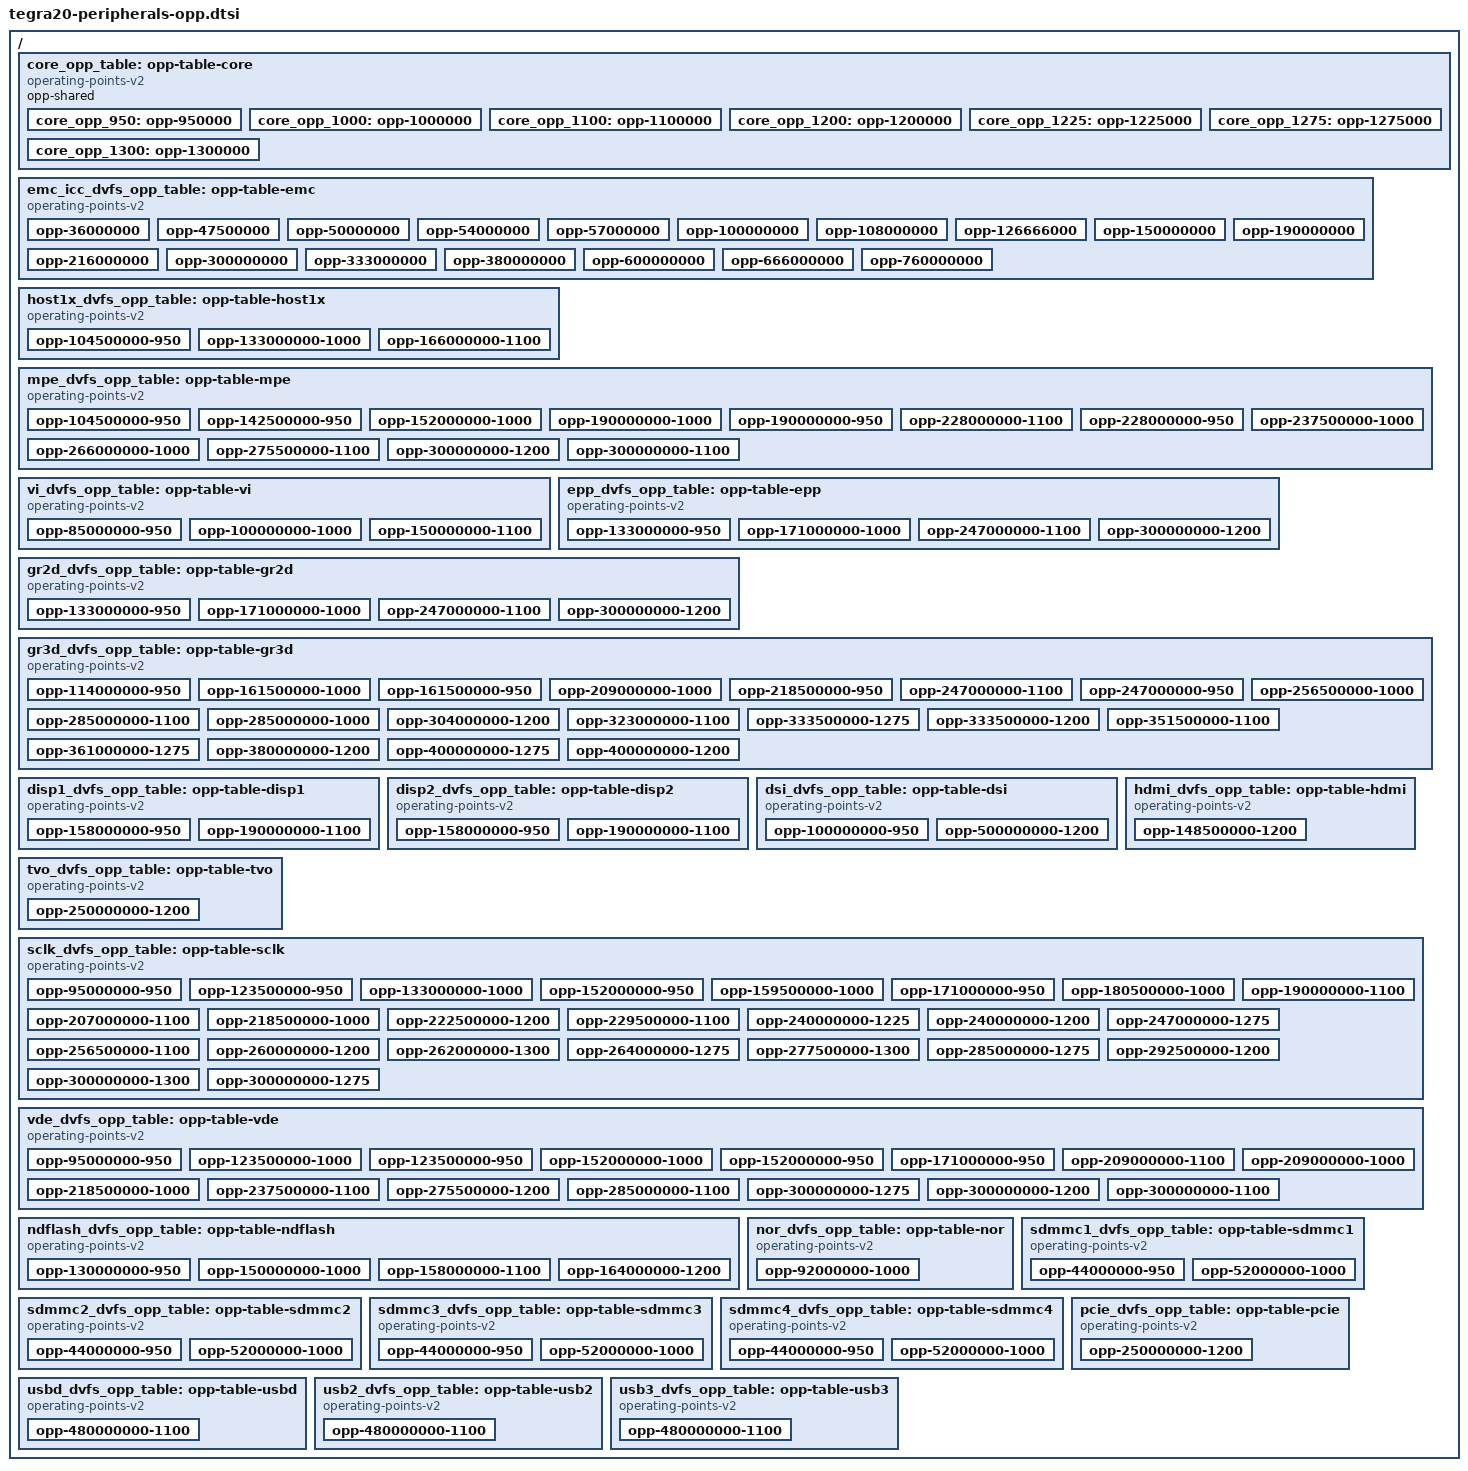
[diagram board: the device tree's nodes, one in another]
// SPDX-License-Identifier: GPL-2.0

/ {
	core_opp_table: opp-table-core {
		compatible = "operating-points-v2";
		opp-shared;

		core_opp_950: opp-950000 {
			opp-microvolt = <950000 950000 1300000>;
			opp-level = <950000>;
		};

		core_opp_1000: opp-1000000 {
			opp-microvolt = <1000000 1000000 1300000>;
			opp-level = <1000000>;
		};

		core_opp_1100: opp-1100000 {
			opp-microvolt = <1100000 1100000 1300000>;
			opp-level = <1100000>;
		};

		core_opp_1200: opp-1200000 {
			opp-microvolt = <1200000 1200000 1300000>;
			opp-level = <1200000>;
		};

		core_opp_1225: opp-1225000 {
			opp-microvolt = <1225000 1225000 1300000>;
			opp-level = <1225000>;
		};

		core_opp_1275: opp-1275000 {
			opp-microvolt = <1275000 1275000 1300000>;
			opp-level = <1275000>;
		};

		core_opp_1300: opp-1300000 {
			opp-microvolt = <1300000 1300000 1300000>;
			opp-level = <1300000>;
		};
	};

	emc_icc_dvfs_opp_table: opp-table-emc {
		compatible = "operating-points-v2";

		opp-36000000 {
			opp-microvolt = <950000 950000 1300000>;
			opp-hz = /bits/ 64 <36000000>;
			opp-supported-hw = <0x000F>;
			required-opps = <&core_opp_950>;
		};

		opp-47500000 {
			opp-microvolt = <950000 950000 1300000>;
			opp-hz = /bits/ 64 <47500000>;
			opp-supported-hw = <0x000F>;
			required-opps = <&core_opp_950>;
		};

		opp-50000000 {
			opp-microvolt = <950000 950000 1300000>;
			opp-hz = /bits/ 64 <50000000>;
			opp-supported-hw = <0x000F>;
			required-opps = <&core_opp_950>;
		};

		opp-54000000 {
			opp-microvolt = <950000 950000 1300000>;
			opp-hz = /bits/ 64 <54000000>;
			opp-supported-hw = <0x000F>;
			required-opps = <&core_opp_950>;
		};

		opp-57000000 {
			opp-microvolt = <950000 950000 1300000>;
			opp-hz = /bits/ 64 <57000000>;
			opp-supported-hw = <0x000F>;
			required-opps = <&core_opp_950>;
		};

		opp-100000000 {
			opp-microvolt = <1000000 1000000 1300000>;
			opp-hz = /bits/ 64 <100000000>;
			opp-supported-hw = <0x000F>;
			required-opps = <&core_opp_1000>;
		};

		opp-108000000 {
			opp-microvolt = <1000000 1000000 1300000>;
			opp-hz = /bits/ 64 <108000000>;
			opp-supported-hw = <0x000F>;
			required-opps = <&core_opp_1000>;
		};

		opp-126666000 {
			opp-microvolt = <1000000 1000000 1300000>;
			opp-hz = /bits/ 64 <126666000>;
			opp-supported-hw = <0x000F>;
			required-opps = <&core_opp_1000>;
		};

		opp-150000000 {
			opp-microvolt = <1000000 1000000 1300000>;
			opp-hz = /bits/ 64 <150000000>;
			opp-supported-hw = <0x000F>;
			required-opps = <&core_opp_1000>;
		};

		opp-190000000 {
			opp-microvolt = <1000000 1000000 1300000>;
			opp-hz = /bits/ 64 <190000000>;
			opp-supported-hw = <0x000F>;
			required-opps = <&core_opp_1000>;
		};

		opp-216000000 {
			opp-microvolt = <1000000 1000000 1300000>;
			opp-hz = /bits/ 64 <216000000>;
			opp-supported-hw = <0x000F>;
			required-opps = <&core_opp_1000>;
			opp-suspend;
		};

		opp-300000000 {
			opp-microvolt = <1000000 1000000 1300000>;
			opp-hz = /bits/ 64 <300000000>;
			opp-supported-hw = <0x000F>;
			required-opps = <&core_opp_1000>;
		};

		opp-333000000 {
			opp-microvolt = <1000000 1000000 1300000>;
			opp-hz = /bits/ 64 <333000000>;
			opp-supported-hw = <0x000F>;
			required-opps = <&core_opp_1000>;
		};

		opp-380000000 {
			opp-microvolt = <1100000 1100000 1300000>;
			opp-hz = /bits/ 64 <380000000>;
			opp-supported-hw = <0x000F>;
			required-opps = <&core_opp_1100>;
		};

		opp-600000000 {
			opp-microvolt = <1200000 1200000 1300000>;
			opp-hz = /bits/ 64 <600000000>;
			opp-supported-hw = <0x000F>;
			required-opps = <&core_opp_1200>;
		};

		opp-666000000 {
			opp-microvolt = <1200000 1200000 1300000>;
			opp-hz = /bits/ 64 <666000000>;
			opp-supported-hw = <0x000F>;
			required-opps = <&core_opp_1200>;
		};

		opp-760000000 {
			opp-microvolt = <1300000 1300000 1300000>;
			opp-hz = /bits/ 64 <760000000>;
			opp-supported-hw = <0x000F>;
			required-opps = <&core_opp_1300>;
		};
	};

	host1x_dvfs_opp_table: opp-table-host1x {
		compatible = "operating-points-v2";

		opp-104500000-950 {
			opp-microvolt = <950000 950000 1300000>;
			opp-hz = /bits/ 64 <104500000>;
			opp-supported-hw = <0x000F>;
			required-opps = <&core_opp_950>;
		};

		opp-133000000-1000 {
			opp-microvolt = <1000000 1000000 1300000>;
			opp-hz = /bits/ 64 <133000000>;
			opp-supported-hw = <0x000F>;
			required-opps = <&core_opp_1000>;
		};

		opp-166000000-1100 {
			opp-microvolt = <1100000 1100000 1300000>;
			opp-hz = /bits/ 64 <166000000>;
			opp-supported-hw = <0x000F>;
			required-opps = <&core_opp_1100>;
		};
	};

	mpe_dvfs_opp_table: opp-table-mpe {
		compatible = "operating-points-v2";

		opp-104500000-950 {
			opp-microvolt = <950000 950000 1300000>;
			opp-hz = /bits/ 64 <104500000>;
			opp-supported-hw = <0x0001>;
			required-opps = <&core_opp_950>;
		};

		opp-142500000-950 {
			opp-microvolt = <950000 950000 1300000>;
			opp-hz = /bits/ 64 <142500000>;
			opp-supported-hw = <0x0002>;
			required-opps = <&core_opp_950>;
		};

		opp-152000000-1000 {
			opp-microvolt = <1000000 1000000 1300000>;
			opp-hz = /bits/ 64 <152000000>;
			opp-supported-hw = <0x0001>;
			required-opps = <&core_opp_1000>;
		};

		opp-190000000-1000 {
			opp-microvolt = <1000000 1000000 1300000>;
			opp-hz = /bits/ 64 <190000000>;
			opp-supported-hw = <0x0002>;
			required-opps = <&core_opp_1000>;
		};

		opp-190000000-950 {
			opp-microvolt = <950000 950000 1300000>;
			opp-hz = /bits/ 64 <190000000>;
			opp-supported-hw = <0x0004>;
			required-opps = <&core_opp_950>;
		};

		opp-228000000-1100 {
			opp-microvolt = <1100000 1100000 1300000>;
			opp-hz = /bits/ 64 <228000000>;
			opp-supported-hw = <0x0001>;
			required-opps = <&core_opp_1100>;
		};

		opp-228000000-950 {
			opp-microvolt = <950000 950000 1300000>;
			opp-hz = /bits/ 64 <228000000>;
			opp-supported-hw = <0x0008>;
			required-opps = <&core_opp_950>;
		};

		opp-237500000-1000 {
			opp-microvolt = <1000000 1000000 1300000>;
			opp-hz = /bits/ 64 <237500000>;
			opp-supported-hw = <0x0004>;
			required-opps = <&core_opp_1000>;
		};

		opp-266000000-1000 {
			opp-microvolt = <1000000 1000000 1300000>;
			opp-hz = /bits/ 64 <266000000>;
			opp-supported-hw = <0x0008>;
			required-opps = <&core_opp_1000>;
		};

		opp-275500000-1100 {
			opp-microvolt = <1100000 1100000 1300000>;
			opp-hz = /bits/ 64 <275500000>;
			opp-supported-hw = <0x0002>;
			required-opps = <&core_opp_1100>;
		};

		opp-300000000-1200 {
			opp-microvolt = <1200000 1200000 1300000>;
			opp-hz = /bits/ 64 <300000000>;
			opp-supported-hw = <0x0003>;
			required-opps = <&core_opp_1200>;
		};

		opp-300000000-1100 {
			opp-microvolt = <1100000 1100000 1300000>;
			opp-hz = /bits/ 64 <300000000>;
			opp-supported-hw = <0x000C>;
			required-opps = <&core_opp_1100>;
		};
	};

	vi_dvfs_opp_table: opp-table-vi {
		compatible = "operating-points-v2";

		opp-85000000-950 {
			opp-microvolt = <950000 950000 1300000>;
			opp-hz = /bits/ 64 <85000000>;
			opp-supported-hw = <0x000F>;
			required-opps = <&core_opp_950>;
		};

		opp-100000000-1000 {
			opp-microvolt = <1000000 1000000 1300000>;
			opp-hz = /bits/ 64 <100000000>;
			opp-supported-hw = <0x000F>;
			required-opps = <&core_opp_1000>;
		};

		opp-150000000-1100 {
			opp-microvolt = <1100000 1100000 1300000>;
			opp-hz = /bits/ 64 <150000000>;
			opp-supported-hw = <0x000F>;
			required-opps = <&core_opp_1100>;
		};
	};

	epp_dvfs_opp_table: opp-table-epp {
		compatible = "operating-points-v2";

		opp-133000000-950 {
			opp-microvolt = <950000 950000 1300000>;
			opp-hz = /bits/ 64 <133000000>;
			opp-supported-hw = <0x000F>;
			required-opps = <&core_opp_950>;
		};

		opp-171000000-1000 {
			opp-microvolt = <1000000 1000000 1300000>;
			opp-hz = /bits/ 64 <171000000>;
			opp-supported-hw = <0x000F>;
			required-opps = <&core_opp_1000>;
		};

		opp-247000000-1100 {
			opp-microvolt = <1100000 1100000 1300000>;
			opp-hz = /bits/ 64 <247000000>;
			opp-supported-hw = <0x000F>;
			required-opps = <&core_opp_1100>;
		};

		opp-300000000-1200 {
			opp-microvolt = <1200000 1200000 1300000>;
			opp-hz = /bits/ 64 <300000000>;
			opp-supported-hw = <0x000F>;
			required-opps = <&core_opp_1200>;
		};
	};

	gr2d_dvfs_opp_table: opp-table-gr2d {
		compatible = "operating-points-v2";

		opp-133000000-950 {
			opp-microvolt = <950000 950000 1300000>;
			opp-hz = /bits/ 64 <133000000>;
			opp-supported-hw = <0x000F>;
			required-opps = <&core_opp_950>;
		};

		opp-171000000-1000 {
			opp-microvolt = <1000000 1000000 1300000>;
			opp-hz = /bits/ 64 <171000000>;
			opp-supported-hw = <0x000F>;
			required-opps = <&core_opp_1000>;
		};

		opp-247000000-1100 {
			opp-microvolt = <1100000 1100000 1300000>;
			opp-hz = /bits/ 64 <247000000>;
			opp-supported-hw = <0x000F>;
			required-opps = <&core_opp_1100>;
		};

		opp-300000000-1200 {
			opp-microvolt = <1200000 1200000 1300000>;
			opp-hz = /bits/ 64 <300000000>;
			opp-supported-hw = <0x000F>;
			required-opps = <&core_opp_1200>;
		};
	};

	gr3d_dvfs_opp_table: opp-table-gr3d {
		compatible = "operating-points-v2";

		opp-114000000-950 {
			opp-microvolt = <950000 950000 1300000>;
			opp-hz = /bits/ 64 <114000000>;
			opp-supported-hw = <0x0001>;
			required-opps = <&core_opp_950>;
		};

		opp-161500000-1000 {
			opp-microvolt = <1000000 1000000 1300000>;
			opp-hz = /bits/ 64 <161500000>;
			opp-supported-hw = <0x0001>;
			required-opps = <&core_opp_1000>;
		};

		opp-161500000-950 {
			opp-microvolt = <950000 950000 1300000>;
			opp-hz = /bits/ 64 <161500000>;
			opp-supported-hw = <0x0002>;
			required-opps = <&core_opp_950>;
		};

		opp-209000000-1000 {
			opp-microvolt = <1000000 1000000 1300000>;
			opp-hz = /bits/ 64 <209000000>;
			opp-supported-hw = <0x0002>;
			required-opps = <&core_opp_1000>;
		};

		opp-218500000-950 {
			opp-microvolt = <950000 950000 1300000>;
			opp-hz = /bits/ 64 <218500000>;
			opp-supported-hw = <0x0004>;
			required-opps = <&core_opp_950>;
		};

		opp-247000000-1100 {
			opp-microvolt = <1100000 1100000 1300000>;
			opp-hz = /bits/ 64 <247000000>;
			opp-supported-hw = <0x0001>;
			required-opps = <&core_opp_1100>;
		};

		opp-247000000-950 {
			opp-microvolt = <950000 950000 1300000>;
			opp-hz = /bits/ 64 <247000000>;
			opp-supported-hw = <0x0008>;
			required-opps = <&core_opp_950>;
		};

		opp-256500000-1000 {
			opp-microvolt = <1000000 1000000 1300000>;
			opp-hz = /bits/ 64 <256500000>;
			opp-supported-hw = <0x0004>;
			required-opps = <&core_opp_1000>;
		};

		opp-285000000-1100 {
			opp-microvolt = <1100000 1100000 1300000>;
			opp-hz = /bits/ 64 <285000000>;
			opp-supported-hw = <0x0002>;
			required-opps = <&core_opp_1100>;
		};

		opp-285000000-1000 {
			opp-microvolt = <1000000 1000000 1300000>;
			opp-hz = /bits/ 64 <285000000>;
			opp-supported-hw = <0x0008>;
			required-opps = <&core_opp_1000>;
		};

		opp-304000000-1200 {
			opp-microvolt = <1200000 1200000 1300000>;
			opp-hz = /bits/ 64 <304000000>;
			opp-supported-hw = <0x0001>;
			required-opps = <&core_opp_1200>;
		};

		opp-323000000-1100 {
			opp-microvolt = <1100000 1100000 1300000>;
			opp-hz = /bits/ 64 <323000000>;
			opp-supported-hw = <0x0004>;
			required-opps = <&core_opp_1100>;
		};

		opp-333500000-1275 {
			opp-microvolt = <1275000 1275000 1300000>;
			opp-hz = /bits/ 64 <333500000>;
			opp-supported-hw = <0x0001>;
			required-opps = <&core_opp_1275>;
		};

		opp-333500000-1200 {
			opp-microvolt = <1200000 1200000 1300000>;
			opp-hz = /bits/ 64 <333500000>;
			opp-supported-hw = <0x0002>;
			required-opps = <&core_opp_1200>;
		};

		opp-351500000-1100 {
			opp-microvolt = <1100000 1100000 1300000>;
			opp-hz = /bits/ 64 <351500000>;
			opp-supported-hw = <0x0008>;
			required-opps = <&core_opp_1100>;
		};

		opp-361000000-1275 {
			opp-microvolt = <1275000 1275000 1300000>;
			opp-hz = /bits/ 64 <361000000>;
			opp-supported-hw = <0x0002>;
			required-opps = <&core_opp_1275>;
		};

		opp-380000000-1200 {
			opp-microvolt = <1200000 1200000 1300000>;
			opp-hz = /bits/ 64 <380000000>;
			opp-supported-hw = <0x0004>;
			required-opps = <&core_opp_1200>;
		};

		opp-400000000-1275 {
			opp-microvolt = <1275000 1275000 1300000>;
			opp-hz = /bits/ 64 <400000000>;
			opp-supported-hw = <0x0004>;
			required-opps = <&core_opp_1275>;
		};

		opp-400000000-1200 {
			opp-microvolt = <1200000 1200000 1300000>;
			opp-hz = /bits/ 64 <400000000>;
			opp-supported-hw = <0x0008>;
			required-opps = <&core_opp_1200>;
		};
	};

	disp1_dvfs_opp_table: opp-table-disp1 {
		compatible = "operating-points-v2";

		opp-158000000-950 {
			opp-microvolt = <950000 950000 1300000>;
			opp-hz = /bits/ 64 <158000000>;
			opp-supported-hw = <0x000F>;
			required-opps = <&core_opp_950>;
		};

		opp-190000000-1100 {
			opp-microvolt = <1100000 1100000 1300000>;
			opp-hz = /bits/ 64 <190000000>;
			opp-supported-hw = <0x000F>;
			required-opps = <&core_opp_1100>;
		};
	};

	disp2_dvfs_opp_table: opp-table-disp2 {
		compatible = "operating-points-v2";

		opp-158000000-950 {
			opp-microvolt = <950000 950000 1300000>;
			opp-hz = /bits/ 64 <158000000>;
			opp-supported-hw = <0x000F>;
			required-opps = <&core_opp_950>;
		};

		opp-190000000-1100 {
			opp-microvolt = <1100000 1100000 1300000>;
			opp-hz = /bits/ 64 <190000000>;
			opp-supported-hw = <0x000F>;
			required-opps = <&core_opp_1100>;
		};
	};

	dsi_dvfs_opp_table: opp-table-dsi {
		compatible = "operating-points-v2";

		opp-100000000-950 {
			opp-microvolt = <950000 950000 1300000>;
			opp-hz = /bits/ 64 <100000000>;
			opp-supported-hw = <0x000F>;
			required-opps = <&core_opp_950>;
		};

		opp-500000000-1200 {
			opp-microvolt = <1200000 1200000 1300000>;
			opp-hz = /bits/ 64 <500000000>;
			opp-supported-hw = <0x000F>;
			required-opps = <&core_opp_1200>;
		};
	};

	hdmi_dvfs_opp_table: opp-table-hdmi {
		compatible = "operating-points-v2";

		opp-148500000-1200 {
			opp-microvolt = <1200000 1200000 1300000>;
			opp-hz = /bits/ 64 <148500000>;
			opp-supported-hw = <0x000F>;
			required-opps = <&core_opp_1200>;
		};
	};

	tvo_dvfs_opp_table: opp-table-tvo {
		compatible = "operating-points-v2";

		opp-250000000-1200 {
			opp-microvolt = <1200000 1200000 1300000>;
			opp-hz = /bits/ 64 <250000000>;
			opp-supported-hw = <0x000F>;
			required-opps = <&core_opp_1200>;
		};
	};

	sclk_dvfs_opp_table: opp-table-sclk {
		compatible = "operating-points-v2";

		opp-95000000-950 {
			opp-microvolt = <950000 950000 1300000>;
			opp-hz = /bits/ 64 <95000000>;
			opp-supported-hw = <0x0001>;
			required-opps = <&core_opp_950>;
		};

		opp-123500000-950 {
			opp-microvolt = <950000 950000 1300000>;
			opp-hz = /bits/ 64 <123500000>;
			opp-supported-hw = <0x0002>;
			required-opps = <&core_opp_950>;
		};

		opp-133000000-1000 {
			opp-microvolt = <1000000 1000000 1300000>;
			opp-hz = /bits/ 64 <133000000>;
			opp-supported-hw = <0x0001>;
			required-opps = <&core_opp_1000>;
		};

		opp-152000000-950 {
			opp-microvolt = <950000 950000 1300000>;
			opp-hz = /bits/ 64 <152000000>;
			opp-supported-hw = <0x0004>;
			required-opps = <&core_opp_950>;
		};

		opp-159500000-1000 {
			opp-microvolt = <1000000 1000000 1300000>;
			opp-hz = /bits/ 64 <159500000>;
			opp-supported-hw = <0x0002>;
			required-opps = <&core_opp_1000>;
		};

		opp-171000000-950 {
			opp-microvolt = <950000 950000 1300000>;
			opp-hz = /bits/ 64 <171000000>;
			opp-supported-hw = <0x0008>;
			required-opps = <&core_opp_950>;
		};

		opp-180500000-1000 {
			opp-microvolt = <1000000 1000000 1300000>;
			opp-hz = /bits/ 64 <180500000>;
			opp-supported-hw = <0x0004>;
			required-opps = <&core_opp_1000>;
		};

		opp-190000000-1100 {
			opp-microvolt = <1100000 1100000 1300000>;
			opp-hz = /bits/ 64 <190000000>;
			opp-supported-hw = <0x0001>;
			required-opps = <&core_opp_1100>;
		};

		opp-207000000-1100 {
			opp-microvolt = <1100000 1100000 1300000>;
			opp-hz = /bits/ 64 <207000000>;
			opp-supported-hw = <0x0002>;
			required-opps = <&core_opp_1100>;
		};

		opp-218500000-1000 {
			opp-microvolt = <1000000 1000000 1300000>;
			opp-hz = /bits/ 64 <218500000>;
			opp-supported-hw = <0x0008>;
			required-opps = <&core_opp_1000>;
		};

		opp-222500000-1200 {
			opp-microvolt = <1200000 1200000 1300000>;
			opp-hz = /bits/ 64 <222500000>;
			opp-supported-hw = <0x0001>;
			required-opps = <&core_opp_1200>;
		};

		opp-229500000-1100 {
			opp-microvolt = <1100000 1100000 1300000>;
			opp-hz = /bits/ 64 <229500000>;
			opp-supported-hw = <0x0004>;
			required-opps = <&core_opp_1100>;
		};

		opp-240000000-1225 {
			opp-microvolt = <1225000 1225000 1300000>;
			opp-hz = /bits/ 64 <240000000>;
			opp-supported-hw = <0x0001>;
			required-opps = <&core_opp_1225>;
		};

		opp-240000000-1200 {
			opp-microvolt = <1200000 1200000 1300000>;
			opp-hz = /bits/ 64 <240000000>;
			opp-supported-hw = <0x0002>;
			required-opps = <&core_opp_1200>;
		};

		opp-247000000-1275 {
			opp-microvolt = <1275000 1275000 1300000>;
			opp-hz = /bits/ 64 <247000000>;
			opp-supported-hw = <0x0001>;
			required-opps = <&core_opp_1275>;
		};

		opp-256500000-1100 {
			opp-microvolt = <1100000 1100000 1300000>;
			opp-hz = /bits/ 64 <256500000>;
			opp-supported-hw = <0x0008>;
			required-opps = <&core_opp_1100>;
		};

		opp-260000000-1200 {
			opp-microvolt = <1200000 1200000 1300000>;
			opp-hz = /bits/ 64 <260000000>;
			opp-supported-hw = <0x0004>;
			required-opps = <&core_opp_1200>;
		};

		opp-262000000-1300 {
			opp-microvolt = <1300000 1300000 1300000>;
			opp-hz = /bits/ 64 <262000000>;
			opp-supported-hw = <0x0001>;
			required-opps = <&core_opp_1300>;
		};

		opp-264000000-1275 {
			opp-microvolt = <1275000 1275000 1300000>;
			opp-hz = /bits/ 64 <264000000>;
			opp-supported-hw = <0x0002>;
			required-opps = <&core_opp_1275>;
		};

		opp-277500000-1300 {
			opp-microvolt = <1300000 1300000 1300000>;
			opp-hz = /bits/ 64 <277500000>;
			opp-supported-hw = <0x0002>;
			required-opps = <&core_opp_1300>;
		};

		opp-285000000-1275 {
			opp-microvolt = <1275000 1275000 1300000>;
			opp-hz = /bits/ 64 <285000000>;
			opp-supported-hw = <0x0004>;
			required-opps = <&core_opp_1275>;
		};

		opp-292500000-1200 {
			opp-microvolt = <1200000 1200000 1300000>;
			opp-hz = /bits/ 64 <292500000>;
			opp-supported-hw = <0x0008>;
			required-opps = <&core_opp_1200>;
		};

		opp-300000000-1300 {
			opp-microvolt = <1300000 1300000 1300000>;
			opp-hz = /bits/ 64 <300000000>;
			opp-supported-hw = <0x0004>;
			required-opps = <&core_opp_1300>;
		};

		opp-300000000-1275 {
			opp-microvolt = <1275000 1275000 1300000>;
			opp-hz = /bits/ 64 <300000000>;
			opp-supported-hw = <0x0008>;
			required-opps = <&core_opp_1275>;
		};
	};

	vde_dvfs_opp_table: opp-table-vde {
		compatible = "operating-points-v2";

		opp-95000000-950 {
			opp-microvolt = <950000 950000 1300000>;
			opp-hz = /bits/ 64 <95000000>;
			opp-supported-hw = <0x0001>;
			required-opps = <&core_opp_950>;
		};

		opp-123500000-1000 {
			opp-microvolt = <1000000 1000000 1300000>;
			opp-hz = /bits/ 64 <123500000>;
			opp-supported-hw = <0x0001>;
			required-opps = <&core_opp_1000>;
		};

		opp-123500000-950 {
			opp-microvolt = <950000 950000 1300000>;
			opp-hz = /bits/ 64 <123500000>;
			opp-supported-hw = <0x0002>;
			required-opps = <&core_opp_950>;
		};

		opp-152000000-1000 {
			opp-microvolt = <1000000 1000000 1300000>;
			opp-hz = /bits/ 64 <152000000>;
			opp-supported-hw = <0x0002>;
			required-opps = <&core_opp_1000>;
		};

		opp-152000000-950 {
			opp-microvolt = <950000 950000 1300000>;
			opp-hz = /bits/ 64 <152000000>;
			opp-supported-hw = <0x0004>;
			required-opps = <&core_opp_950>;
		};

		opp-171000000-950 {
			opp-microvolt = <950000 950000 1300000>;
			opp-hz = /bits/ 64 <171000000>;
			opp-supported-hw = <0x0008>;
			required-opps = <&core_opp_950>;
		};

		opp-209000000-1100 {
			opp-microvolt = <1100000 1100000 1300000>;
			opp-hz = /bits/ 64 <209000000>;
			opp-supported-hw = <0x0001>;
			required-opps = <&core_opp_1100>;
		};

		opp-209000000-1000 {
			opp-microvolt = <1000000 1000000 1300000>;
			opp-hz = /bits/ 64 <209000000>;
			opp-supported-hw = <0x0004>;
			required-opps = <&core_opp_1000>;
		};

		opp-218500000-1000 {
			opp-microvolt = <1000000 1000000 1300000>;
			opp-hz = /bits/ 64 <218500000>;
			opp-supported-hw = <0x0008>;
			required-opps = <&core_opp_1000>;
		};

		opp-237500000-1100 {
			opp-microvolt = <1100000 1100000 1300000>;
			opp-hz = /bits/ 64 <237500000>;
			opp-supported-hw = <0x0002>;
			required-opps = <&core_opp_1100>;
		};

		opp-275500000-1200 {
			opp-microvolt = <1200000 1200000 1300000>;
			opp-hz = /bits/ 64 <275500000>;
			opp-supported-hw = <0x0001>;
			required-opps = <&core_opp_1200>;
		};

		opp-285000000-1100 {
			opp-microvolt = <1100000 1100000 1300000>;
			opp-hz = /bits/ 64 <285000000>;
			opp-supported-hw = <0x0004>;
			required-opps = <&core_opp_1100>;
		};

		opp-300000000-1275 {
			opp-microvolt = <1275000 1275000 1300000>;
			opp-hz = /bits/ 64 <300000000>;
			opp-supported-hw = <0x0001>;
			required-opps = <&core_opp_1275>;
		};

		opp-300000000-1200 {
			opp-microvolt = <1200000 1200000 1300000>;
			opp-hz = /bits/ 64 <300000000>;
			opp-supported-hw = <0x0006>;
			required-opps = <&core_opp_1200>;
		};

		opp-300000000-1100 {
			opp-microvolt = <1100000 1100000 1300000>;
			opp-hz = /bits/ 64 <300000000>;
			opp-supported-hw = <0x0008>;
			required-opps = <&core_opp_1100>;
		};
	};

	ndflash_dvfs_opp_table: opp-table-ndflash {
		compatible = "operating-points-v2";

		opp-130000000-950 {
			opp-microvolt = <950000 950000 1300000>;
			opp-hz = /bits/ 64 <130000000>;
			opp-supported-hw = <0x000F>;
			required-opps = <&core_opp_950>;
		};

		opp-150000000-1000 {
			opp-microvolt = <1000000 1000000 1300000>;
			opp-hz = /bits/ 64 <150000000>;
			opp-supported-hw = <0x000F>;
			required-opps = <&core_opp_1000>;
		};

		opp-158000000-1100 {
			opp-microvolt = <1100000 1100000 1300000>;
			opp-hz = /bits/ 64 <158000000>;
			opp-supported-hw = <0x000F>;
			required-opps = <&core_opp_1100>;
		};

		opp-164000000-1200 {
			opp-microvolt = <1200000 1200000 1300000>;
			opp-hz = /bits/ 64 <164000000>;
			opp-supported-hw = <0x000F>;
			required-opps = <&core_opp_1200>;
		};
	};

	nor_dvfs_opp_table: opp-table-nor {
		compatible = "operating-points-v2";

		opp-92000000-1000 {
			opp-microvolt = <1000000 1000000 1300000>;
			opp-hz = /bits/ 64 <92000000>;
			opp-supported-hw = <0x000F>;
			required-opps = <&core_opp_1000>;
		};
	};

	sdmmc1_dvfs_opp_table: opp-table-sdmmc1 {
		compatible = "operating-points-v2";

		opp-44000000-950 {
			opp-microvolt = <950000 950000 1300000>;
			opp-hz = /bits/ 64 <44000000>;
			opp-supported-hw = <0x000F>;
			required-opps = <&core_opp_950>;
		};

		opp-52000000-1000 {
			opp-microvolt = <1000000 1000000 1300000>;
			opp-hz = /bits/ 64 <52000000>;
			opp-supported-hw = <0x000F>;
			required-opps = <&core_opp_1000>;
		};
	};

	sdmmc2_dvfs_opp_table: opp-table-sdmmc2 {
		compatible = "operating-points-v2";

		opp-44000000-950 {
			opp-microvolt = <950000 950000 1300000>;
			opp-hz = /bits/ 64 <44000000>;
			opp-supported-hw = <0x000F>;
			required-opps = <&core_opp_950>;
		};

		opp-52000000-1000 {
			opp-microvolt = <1000000 1000000 1300000>;
			opp-hz = /bits/ 64 <52000000>;
			opp-supported-hw = <0x000F>;
			required-opps = <&core_opp_1000>;
		};
	};

	sdmmc3_dvfs_opp_table: opp-table-sdmmc3 {
		compatible = "operating-points-v2";

		opp-44000000-950 {
			opp-microvolt = <950000 950000 1300000>;
			opp-hz = /bits/ 64 <44000000>;
			opp-supported-hw = <0x000F>;
			required-opps = <&core_opp_950>;
		};

		opp-52000000-1000 {
			opp-microvolt = <1000000 1000000 1300000>;
			opp-hz = /bits/ 64 <52000000>;
			opp-supported-hw = <0x000F>;
			required-opps = <&core_opp_1000>;
		};
	};

	sdmmc4_dvfs_opp_table: opp-table-sdmmc4 {
		compatible = "operating-points-v2";

		opp-44000000-950 {
			opp-microvolt = <950000 950000 1300000>;
			opp-hz = /bits/ 64 <44000000>;
			opp-supported-hw = <0x000F>;
			required-opps = <&core_opp_950>;
		};

		opp-52000000-1000 {
			opp-microvolt = <1000000 1000000 1300000>;
			opp-hz = /bits/ 64 <52000000>;
			opp-supported-hw = <0x000F>;
			required-opps = <&core_opp_1000>;
		};
	};

	pcie_dvfs_opp_table: opp-table-pcie {
		compatible = "operating-points-v2";

		opp-250000000-1200 {
			opp-microvolt = <1200000 1200000 1300000>;
			opp-hz = /bits/ 64 <250000000>;
			opp-supported-hw = <0x000F>;
			required-opps = <&core_opp_1200>;
		};
	};

	usbd_dvfs_opp_table: opp-table-usbd {
		compatible = "operating-points-v2";

		opp-480000000-1100 {
			opp-microvolt = <1100000 1100000 1300000>;
			opp-hz = /bits/ 64 <480000000>;
			opp-supported-hw = <0x000F>;
			required-opps = <&core_opp_1100>;
		};
	};

	usb2_dvfs_opp_table: opp-table-usb2 {
		compatible = "operating-points-v2";

		opp-480000000-1100 {
			opp-microvolt = <1100000 1100000 1300000>;
			opp-hz = /bits/ 64 <480000000>;
			opp-supported-hw = <0x000F>;
			required-opps = <&core_opp_1100>;
		};
	};

	usb3_dvfs_opp_table: opp-table-usb3 {
		compatible = "operating-points-v2";

		opp-480000000-1100 {
			opp-microvolt = <1100000 1100000 1300000>;
			opp-hz = /bits/ 64 <480000000>;
			opp-supported-hw = <0x000F>;
			required-opps = <&core_opp_1100>;
		};
	};
};
